AUTOSAR XML (schema 4-2-2)
package /AUTOLIV/SoftwareComponents/DcmIf
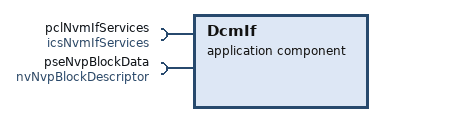
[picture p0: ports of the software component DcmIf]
  application sw component type DcmIf: category=BSW_Communication_Services
    require port pclNvmIfServices: required-interface=icsNvmIfServices  # # Architecture Element ID ARCH_SW_DcmIf_pclNvmIfServices_ReadBlockByAddress # Description - The NvmIf_ReadBlockByAddress runnable will read the memory space specified in the {Start address} input parameter - The NvmIf_ReadBlockByAddress runnable will output the read memory bytes in the {Pointer to the buffer in DcmIf} output parameter # Data Flow ## Inputs - {Start address} (of the memory from which data is to be retrieved) ## Outputs - {Pointer to the buffer in DcmIf} # Linked Runnable - Dcm_ReadMemory #Traceability DOM_eCS_TF_E_490;DOM_eCS_TF_E_491;DOM_eCS_TF_E_1174;DOM_eCS_TF_E_494;DOM_eCS_TF_E_1920 --------------------------------------------------------------------------------------- # Architecture Element ID ARCH_SW_DcmIf_pclNvmIfServices_GetNvmBlockStatus_Dcm_ReadMemory # Description - The NvmIf_GetNvmBlockStatus runnable will return the NvM block status on the {Block Status} output parameter for the selected {Block Id} input parameter # Data Flow ## Inputs - {Block Id} ## Outputs - {Block Status} # Linked Runnable - Dcm_ReadMemory #Traceability --------------------------------------------------------------------------------------- # Architecture Element ID ARCH_SW_DcmIf_pclNvmIfServices_WriteBlockByAddress # Description - The NvmIf_WriteBlockByAddress runnable will write the memory space specified in the {Start address} input parameter with the data from the {Pointer to the buffer in DcmIf} input parameter # Data Flow ## Inputs - {Start address} (of the memory from which data is to be written) ## Outputs - {Pointer to the buffer in DcmIf} # Linked Runnable - Dcm_WriteMemory #Traceability DOM_eCS_TF_E_1008;DOM_eCS_TF_E_1009;DOM_eCS_TF_E_1355;DOM_eCS_TF_E_1357;DOM_eCS_TF_E_1012;DOM_eCS_TF_E_1013;DOM_eCS_TF_E_1354;DOM_eCS_TF_E_2021;DOM_eCS_TF_E_2022;DOM_eCS_TF_E_2024 ------------------------------------------------------------------------------------- # Architecture Element ID ARCH_SW_DcmIf_pclNvmIfServices_GetNvmBlockStatus_Dcm_WriteMemory # Description - The NvmIf_GetNvmBlockStatus runnable will return the NvM block status on the {Block Status} output parameter for the selected {Block Id} input parameter # Data Flow ## Inputs - {Block Id} ## Outputs - {Block Status} # Linked Runnable - Dcm_WriteMemory #Traceability ------------------------------------------------------------------------------------- # Architecture Element ID ARCH_SW_DcmIf_pclNvmIfServices_GetRamAddressByBlockId_Dcm_WriteMemory # Description - The NvmIf_GetRamAddressByBlockId runnable will return the NvM block RAM address on the {BlockRamAddress} output parameter for the selected {Block Id} input parameter # Data Flow ## Inputs - {Block Id} ## Outputs - {BlockRamAddress} # Linked Runnable - Dcm_WriteMemory #Traceability
      required-com-specs:
        NvmIf_GetRamAddressByBlockId
        GetNvmBlockLength
        GetNvmBlockStatus
        ReadBlockByAddress
        RestorePRAMBlockDefaults
        SetRamBlockStatus
        WriteBlockByAddress
        WriteNvmBlock
    require port pseNvpBlockData: required-com-specs=[u8NvpProcessMode, u8NvpEcuLockStatus], required-interface=nvNvpBlockDescriptor  # # Architecture Element ID ARCH_SW_DcmIf_pseNvpBlockData_Dcm_GetProgConditions # Description - The DcmIf module shall be able to use the KU8_ECU_UNLOCK / KU8_ECU_LOCK defines # Data Flow ## Inputs ## Outputs # Linked Runnable - Dcm_WriteMemory #Traceability
    behavior DcmIf_IB: data-type-mapping=[DataTypeMappingSet_DcmIf, DataTypeMappingSet_NVP, DataTypeMappingSet_NvmIf], handle-termination-and-restart=NO-SUPPORT
      5 x runnable:
        Dcm_GetProgConditions: external-triggering-point=ptrpAsrDcmServicesDcmIf.Dcm_GetProgConditions, symbol=Dcm_GetProgConditionsStub
        Dcm_ReadMemory: external-triggering-point=ptrpAsrDcmServicesDcmIf.Dcm_ReadMemory, symbol=Dcm_ReadMemoryStub
          sync call scp_GetNvmBlockStatus: operation=pclNvmIfServices.GetNvmBlockStatus, timeout=0.0
          sync call scp_ReadBlockByAddress: operation=pclNvmIfServices.ReadBlockByAddress, timeout=0.0
        Dcm_SetProgConditions: external-triggering-point=ptrpAsrDcmServicesDcmIf.Dcm_SetProgConditions, symbol=Dcm_SetProgConditionsStub
        Dcm_WriteMemory: external-triggering-point=ptrpAsrDcmServicesDcmIf.Dcm_WriteMemory, symbol=Dcm_WriteMemoryStub
          sync call scp_NvmIf_GetRamAddressByBlo: operation=pclNvmIfServices.NvmIf_GetRamAddressByBlockId, timeout=0.0
          sync call scp_WriteBlockByAddress: operation=pclNvmIfServices.WriteBlockByAddress, timeout=0.0
        Rte_DcmConfirmation: external-triggering-point=ptrpAsrDcmServicesDcmIf.Rte_DcmConfirmation, symbol=Rte_DcmConfirmation_symb
  swc implementation DcmIf_imp: category=BSW_Communication_Services, programming-language=C, sw-version=1.0.0, vendor-id=0, behavior=DcmIf_IB
    code-descriptors:
      code DcmIf_Impl_Code: artifact-descriptors=autosar-engineering-object={short-label=DcmIf_Impl_Code_CodeDesc, category=SWSRC}
    resource consumption DcmIf_Impl_ResCons
      33 x memory section:
        CODE: size=0, sw-addrmethod=CODE
        CODE_ASIL_A: size=0, sw-addrmethod=CODE_ASIL_A
        CONST_16: alignment=16, size=16, sw-addrmethod=CONST
        CONST_16_ASIL_A: alignment=16, size=16, sw-addrmethod=CONST_ASIL_A
        CONST_32: alignment=32, size=32, sw-addrmethod=CONST
        CONST_32_ASIL_A: alignment=32, size=32, sw-addrmethod=CONST_ASIL_A
        CONST_8: alignment=8, size=8, sw-addrmethod=CONST
        CONST_8_ASIL_A: alignment=8, size=8, sw-addrmethod=CONST_ASIL_A
        CONST_BOOL: alignment=8, size=1, sw-addrmethod=CONST
        CONST_BOOL_ASIL_A: alignment=8, size=1, sw-addrmethod=CONST_ASIL_A
        CONST_UNSPECIFIED: alignment=UNSPECIFIED, size=0, sw-addrmethod=CONST
        CONST_UNSPECIFIED_ASIL_A: alignment=UNSPECIFIED, size=0, sw-addrmethod=CONST_ASIL_A
        VAR_INIT_16: alignment=16, size=16, sw-addrmethod=VAR_INIT
        VAR_INIT_16_ASIL_A: alignment=16, size=16, sw-addrmethod=VAR_INIT_ASIL_A
        VAR_INIT_32: alignment=32, size=32, sw-addrmethod=VAR_INIT
        VAR_INIT_32_ASIL_A: alignment=32, size=32, sw-addrmethod=VAR_INIT_ASIL_A
        VAR_INIT_8: alignment=8, size=8, sw-addrmethod=VAR_INIT
        VAR_INIT_8_ASIL_A: alignment=8, size=8, sw-addrmethod=VAR_INIT_ASIL_A
        VAR_INIT_BOOL: alignment=8, size=1, sw-addrmethod=VAR_INIT
        VAR_INIT_BOOL_ASIL_A: alignment=8, size=1, sw-addrmethod=VAR_INIT_ASIL_A
        VAR_INIT_UNSPECIFIED: alignment=UNSPECIFIED, size=0, sw-addrmethod=VAR_INIT
        VAR_INIT_UNSPECIFIED_ASIL_A: alignment=UNSPECIFIED, size=0, sw-addrmethod=VAR_INIT_ASIL_A
        VAR_NO_INIT_16: alignment=16, size=16, sw-addrmethod=VAR_NOINIT
        VAR_NO_INIT_16_ASIL_A: alignment=16, size=16, sw-addrmethod=VAR_NOINIT_ASIL_A
        VAR_NO_INIT_32: alignment=32, size=32, sw-addrmethod=VAR_NOINIT
        VAR_NO_INIT_32_ASIL_A: alignment=32, size=32, sw-addrmethod=VAR_NOINIT_ASIL_A
        VAR_NO_INIT_8: alignment=8, size=8, sw-addrmethod=VAR_NOINIT
        VAR_NO_INIT_8_ASIL_A: alignment=8, size=8, sw-addrmethod=VAR_NOINIT_ASIL_A
        VAR_NO_INIT_BOOL: alignment=8, size=1, sw-addrmethod=VAR_NOINIT
        VAR_NO_INIT_BOOL_ASIL_A: alignment=8, size=1, sw-addrmethod=VAR_NOINIT_ASIL_A
        VAR_NO_INIT_UNSPECIFIED: alignment=UNSPECIFIED, size=0, sw-addrmethod=VAR_NOINIT
        VAR_NO_INIT_UNSPECIFIED_ASIL_A: alignment=UNSPECIFIED, size=0, sw-addrmethod=VAR_NOINIT_ASIL_A
        VAR_POWER_ON_CLEARED: alignment=UNSPECIFIED, size=0, sw-addrmethod=VAR_POWER_ON_CLEARED
